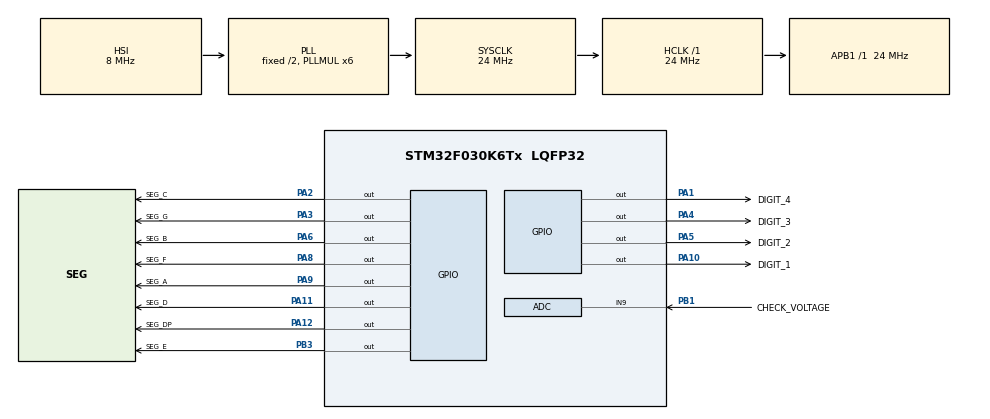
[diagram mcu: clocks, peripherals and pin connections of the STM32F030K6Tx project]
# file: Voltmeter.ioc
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ADC.ContinuousConvMode=ENABLE
ADC.DMAContinuousRequests=ENABLE
ADC.SamplingTime=ADC_SAMPLETIME_239CYCLES_5
Dma.ADC.0.Direction=DMA_PERIPH_TO_MEMORY
Dma.ADC.0.Instance=DMA1_Channel1
Dma.ADC.0.MemDataAlignment=DMA_MDATAALIGN_HALFWORD
Dma.ADC.0.MemInc=DMA_MINC_ENABLE
Dma.ADC.0.Mode=DMA_CIRCULAR
Dma.ADC.0.PeriphDataAlignment=DMA_PDATAALIGN_HALFWORD
Dma.ADC.0.PeriphInc=DMA_PINC_DISABLE
Dma.ADC.0.Priority=DMA_PRIORITY_MEDIUM
Dma.Request0=ADC
Mcu.Family=STM32F0
Mcu.Name=STM32F030K6Tx
Mcu.Package=LQFP32
NVIC.DMA1_Channel1_IRQn=true\:0\:0\:false\:false\:true\:false\:true\:true
NVIC.TIM3_IRQn=true\:0\:0\:false\:false\:true\:true\:true\:true
PA1.GPIO_Label=DIGIT_4
PA1.GPIO_ModeDefaultOutputPP=GPIO_MODE_OUTPUT_PP
PA1.GPIO_PuPd=GPIO_NOPULL
PA1.Signal=GPIO_Output
PA10.GPIO_Label=DIGIT_1
PA10.GPIO_ModeDefaultOutputPP=GPIO_MODE_OUTPUT_PP
PA10.GPIO_PuPd=GPIO_NOPULL
PA10.Signal=GPIO_Output
PA11.GPIO_Label=SEG_D
PA11.GPIO_ModeDefaultOutputPP=GPIO_MODE_OUTPUT_PP
PA11.GPIO_PuPd=GPIO_NOPULL
PA11.Signal=GPIO_Output
PA12.GPIO_Label=SEG_DP
PA12.GPIO_ModeDefaultOutputPP=GPIO_MODE_OUTPUT_PP
PA12.GPIO_PuPd=GPIO_NOPULL
PA12.Signal=GPIO_Output
PA13.Mode=Serial_Wire
PA13.Signal=SYS_SWDIO
PA14.Mode=Serial_Wire
PA14.Signal=SYS_SWCLK
PA2.GPIO_Label=SEG_C
PA2.GPIO_ModeDefaultOutputPP=GPIO_MODE_OUTPUT_PP
PA2.GPIO_PuPd=GPIO_NOPULL
PA2.Signal=GPIO_Output
PA3.GPIO_Label=SEG_G
PA3.GPIO_ModeDefaultOutputPP=GPIO_MODE_OUTPUT_PP
PA3.GPIO_PuPd=GPIO_NOPULL
PA3.Signal=GPIO_Output
PA4.GPIO_Label=DIGIT_3
PA4.GPIO_ModeDefaultOutputPP=GPIO_MODE_OUTPUT_PP
PA4.GPIO_PuPd=GPIO_NOPULL
PA4.Signal=GPIO_Output
PA5.GPIO_Label=DIGIT_2
PA5.GPIO_ModeDefaultOutputPP=GPIO_MODE_OUTPUT_PP
PA5.GPIO_PuPd=GPIO_NOPULL
PA5.Signal=GPIO_Output
PA6.GPIO_Label=SEG_B
PA6.GPIO_ModeDefaultOutputPP=GPIO_MODE_OUTPUT_PP
PA6.GPIO_PuPd=GPIO_NOPULL
PA6.Signal=GPIO_Output
PA8.GPIO_Label=SEG_F
PA8.GPIO_ModeDefaultOutputPP=GPIO_MODE_OUTPUT_PP
PA8.GPIO_PuPd=GPIO_NOPULL
PA8.Signal=GPIO_Output
PA9.GPIO_Label=SEG_A
PA9.GPIO_ModeDefaultOutputPP=GPIO_MODE_OUTPUT_PP
PA9.GPIO_PuPd=GPIO_NOPULL
PA9.Signal=GPIO_Output
PB1.GPIO_Label=CHECK_VOLTAGE
PB1.Mode=IN9
PB1.Signal=ADC_IN9
PB3.GPIO_Label=SEG_E
PB3.GPIO_ModeDefaultOutputPP=GPIO_MODE_OUTPUT_PP
PB3.GPIO_PuPd=GPIO_NOPULL
PB3.Signal=GPIO_Output
ProjectManager.HeapSize=0x200
ProjectManager.StackSize=0x400
ProjectManager.TargetToolchain=STM32CubeIDE
RCC.AHBFreq_Value=24000000
RCC.APB1Freq_Value=24000000
RCC.APB1TimFreq_Value=24000000
RCC.HCLKFreq_Value=24000000
RCC.PLLMUL=RCC_PLL_MUL6
RCC.SYSCLKFreq_VALUE=24000000
RCC.SYSCLKSource=RCC_SYSCLKSOURCE_PLLCLK
RCC.TimSys_Div=SYSTICK_CLKSOURCE_HCLK_DIV8
TIM3.Period=1000
TIM3.Prescaler=23
VP_TIM3_VS_ClockSourceINT.Mode=Internal
board=custom

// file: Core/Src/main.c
/* USER CODE BEGIN Header */
/*
 * 	main.c
 *
 *  Created on	: February 12, 2025
 *  Company		: ASELSAN KONYA
 *  Author		: ABDULLAH HUZEYFE PIROGLU
 *
 */
/* USER CODE END Header */
#include "main.h"
#include "adc.h"
#include "dma.h"
#include "tim.h"
#include "gpio.h"

/* USER CODE BEGIN Includes */
#include "definitions.h"
#include "seven_segment_display.h"
#include "timing.h"
#include "functions.h"

/* USER CODE END Includes */

/* USER CODE BEGIN PV */
voltmeterStructer voltmeter;
/* USER CODE END PV */

void SystemClock_Config(void);

int main(void)
{
  /* USER CODE BEGIN 1 */
	voltmeter.adcValue = 0;
	voltmeter.mode = true;
	voltmeter.blinkFlag = false;
  /* USER CODE END 1 */

  /* MCU Configuration--------------------------------------------------------*/

  /* Reset of all peripherals, Initializes the Flash interface and the Systick. */
  HAL_Init();

  /* Configure the system clock */
  SystemClock_Config();

  /* Initialize all configured peripherals */
  MX_GPIO_Init();
  MX_DMA_Init();
  MX_ADC_Init();
  MX_TIM3_Init();
  /* USER CODE BEGIN 2 */
  HAL_ADC_Start_DMA(&hadc, (uint32_t*)&voltmeter.adcValue, 1);
  HAL_TIM_Base_Start_IT(&htim3);
  /* USER CODE END 2 */

  /* Infinite loop */
  while (1)
  {

    /* USER CODE BEGIN 3 */
	  startTimeScanFlags();
//deneme
//	    DIGIT_CONTROL(DIGIT_1,DIGIT_ON);
//	    DIGIT_CONTROL(DIGIT_2,DIGIT_OFF);
//	    DIGIT_CONTROL(DIGIT_3,DIGIT_OFF);
//	    DIGIT_CONTROL(DIGIT_4,DIGIT_OFF);
//
//	    SEGMENT_CONTROL(SEG_A,SEGMENT_ON);
//	    SEGMENT_CONTROL(SEG_B,SEGMENT_OFF);
//	    SEGMENT_CONTROL(SEG_C,SEGMENT_OFF);
//	    SEGMENT_CONTROL(SEG_D,SEGMENT_OFF);
//	    SEGMENT_CONTROL(SEG_E,SEGMENT_OFF);
//	    SEGMENT_CONTROL(SEG_F,SEGMENT_OFF);
//	    SEGMENT_CONTROL(SEG_G,SEGMENT_OFF);
//	    SEGMENT_CONTROL(SEG_DP,SEGMENT_OFF);

	  //float deneme = low_pass_filter();
	  sevenSegmentDisplaySetNumbers(low_pass_filter());
	  //sevenSegmentDisplaySetNumbers(11.10);

//	  sevenSegmentDisplaySetDigit(0, 0, 2);
//	  sevenSegmentDisplaySetDigit(1, 9, 2);
//	  sevenSegmentDisplaySetDigit(2, 9, 2);
//	  sevenSegmentDisplaySetDigit(3, 0, 2);
	  sevenSegmentDisplayUpdate();

	  clearTimeScanFlags();
  }
  /* USER CODE END 3 */
}

void SystemClock_Config(void)
{
  RCC_OscInitTypeDef RCC_OscInitStruct = {0};
  RCC_ClkInitTypeDef RCC_ClkInitStruct = {0};

  /** Initializes the RCC Oscillators according to the specified parameters
  * in the RCC_OscInitTypeDef structure.
  */
  RCC_OscInitStruct.OscillatorType = RCC_OSCILLATORTYPE_HSI|RCC_OSCILLATORTYPE_HSI14;
  RCC_OscInitStruct.HSIState = RCC_HSI_ON;
  RCC_OscInitStruct.HSI14State = RCC_HSI14_ON;
  RCC_OscInitStruct.HSICalibrationValue = RCC_HSICALIBRATION_DEFAULT;
  RCC_OscInitStruct.HSI14CalibrationValue = 16;
  RCC_OscInitStruct.PLL.PLLState = RCC_PLL_ON;
  RCC_OscInitStruct.PLL.PLLSource = RCC_PLLSOURCE_HSI;
  RCC_OscInitStruct.PLL.PLLMUL = RCC_PLL_MUL6;
  RCC_OscInitStruct.PLL.PREDIV = RCC_PREDIV_DIV1;
  if (HAL_RCC_OscConfig(&RCC_OscInitStruct) != HAL_OK)
  {
    Error_Handler();
  }

  /** Initializes the CPU, AHB and APB buses clocks
  */
  RCC_ClkInitStruct.ClockType = RCC_CLOCKTYPE_HCLK|RCC_CLOCKTYPE_SYSCLK
                              |RCC_CLOCKTYPE_PCLK1;
  RCC_ClkInitStruct.SYSCLKSource = RCC_SYSCLKSOURCE_PLLCLK;
  RCC_ClkInitStruct.AHBCLKDivider = RCC_SYSCLK_DIV1;
  RCC_ClkInitStruct.APB1CLKDivider = RCC_HCLK_DIV1;

  if (HAL_RCC_ClockConfig(&RCC_ClkInitStruct, FLASH_LATENCY_0) != HAL_OK)
  {
    Error_Handler();
  }
}

void Error_Handler(void)
{
  __disable_irq();
  while (1)
  {
  }
}
